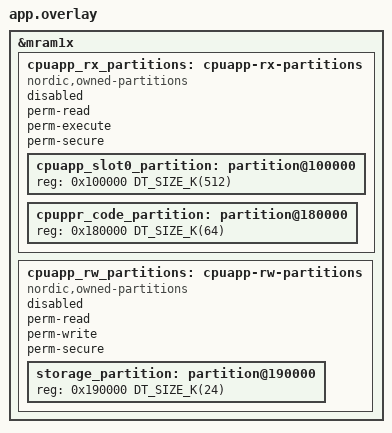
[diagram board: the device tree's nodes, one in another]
/delete-node/ &cpuapp_rx_partitions;
/delete-node/ &cpuapp_rw_partitions;

&mram1x {
	cpuapp_rx_partitions: cpuapp-rx-partitions {
		compatible = "nordic,owned-partitions", "fixed-partitions";
		status = "disabled";
		perm-read;
		perm-execute;
		perm-secure;
		#address-cells = <1>;
		#size-cells = <1>;

		cpuapp_slot0_partition: partition@100000 {
			reg = <0x100000 DT_SIZE_K(512)>;
		};

		cpuppr_code_partition: partition@180000 {
			reg = <0x180000 DT_SIZE_K(64)>;
		};
	};

	cpuapp_rw_partitions: cpuapp-rw-partitions {
		compatible = "nordic,owned-partitions", "fixed-partitions";
		status = "disabled";
		perm-read;
		perm-write;
		perm-secure;
		#address-cells = <1>;
		#size-cells = <1>;

		storage_partition: partition@190000 {
			reg = <0x190000 DT_SIZE_K(24)>;
		};
	};
};
